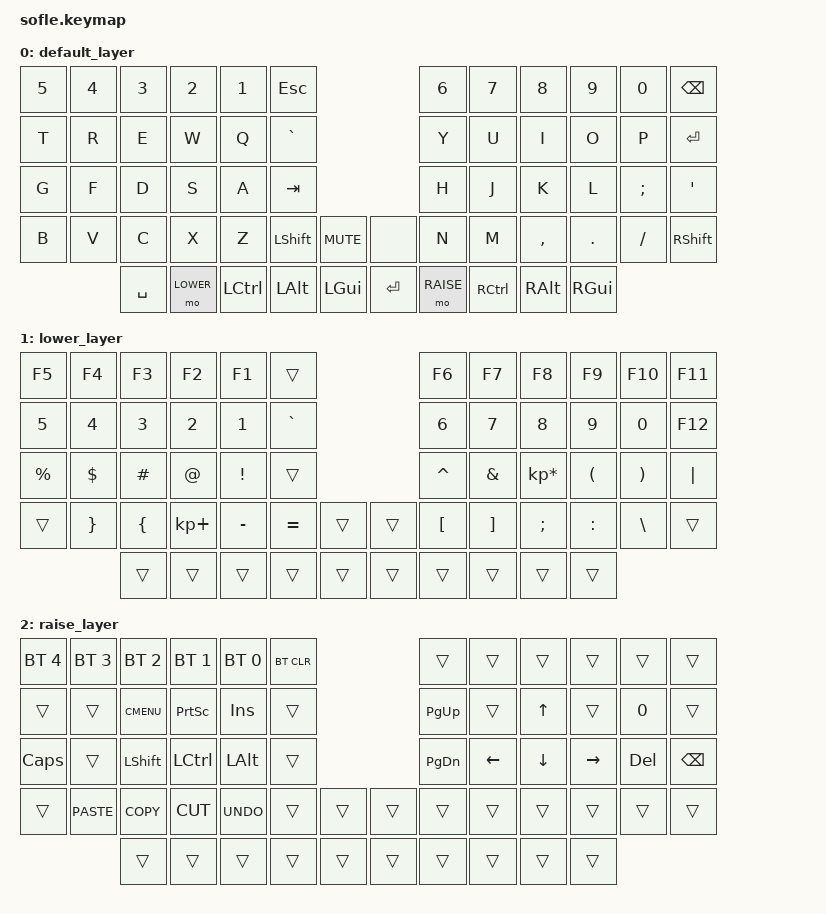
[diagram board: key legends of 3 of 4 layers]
/*
 * Copyright (c) 2020 The ZMK Contributors
 *
 * SPDX-License-Identifier: MIT
 */

#include <behaviors.dtsi>
#include <dt-bindings/zmk/keys.h>
#include <dt-bindings/zmk/bt.h>
#include <dt-bindings/zmk/rgb.h>
#include <dt-bindings/zmk/ext_power.h>

#define BASE 0
#define LOWER 1
#define RAISE 2
#define ADJUST 3

/ {

   // Activate ADJUST layer by pressing raise and lower
    conditional_layers {
        compatible = "zmk,conditional-layers";
        adjust_layer {
            if-layers = <LOWER RAISE>;
            then-layer = <ADJUST>;
        };
    };

    keymap {
        compatible = "zmk,keymap";

        default_layer {
// this is the keyhive variant which is a mirrored layout of the official sofle. be careful
// i.e. `QWERT is TREWQ`
// ------------------------------------------------------------------------------------------------------------
// |  ESC  |  1  |  2  |  3   |  4   |  5   |                   |  6   |  7    |  8    |  9   |   0   | BKSPC |
// |  `    |  Q  |  W  |  E   |  R   |  T   |                   |  Y   |  U    |  I    |  O   |   P   | ENTER |
// |  TAB  |  A  |  S  |  D   |  F   |  G   |                   |  H   |  J    |  K    |  L   |   ;   |   '   |
// | SHIFT |  Z  |  X  |  C   |  V   |  B   |  MUTE  |  |       |  N   |  M    |  ,    |  .   |   /   | SHIFT |
//               | GUI | ALT  | CTRL | LOWER|  SPACE |  | ENTER | RAISE| CTRL  | ALT   | GUI  |
            bindings = <
&kp N5 &kp N4 &kp N3   &kp N2   &kp N1    &kp ESC                      &kp N6 &kp N7    &kp N8    &kp N9   &kp N0   &kp BSPC
&kp  T &kp R  &kp E    &kp W    &kp Q     &kp GRAVE                     &kp Y  &kp U     &kp I     &kp O    &kp P    &kp RET
&kp G  &kp F  &kp D    &kp S    &kp A     &kp TAB                       &kp H  &kp J     &kp K     &kp L    &kp SEMI &kp SQT
&kp B  &kp V  &kp C &kp X       &kp Z     &kp LSHFT  &kp C_MUTE   &none     &kp N  &kp M     &kp COMMA &kp DOT  &kp FSLH &kp RSHFT
                 &kp SPACE &mo LOWER &kp LCTRL &kp LALT &kp LGUI   &kp RET &mo RAISE  &kp RCTRL &kp RALT  &kp RGUI
            >;

            sensor-bindings = <&inc_dec_kp C_VOL_UP C_VOL_DN &inc_dec_kp PG_UP PG_DN>;
        };

        lower_layer {
// TODO: Some binds are waiting for shifted keycode support.
// ------------------------------------------------------------------------------------------------------------
// |       |  F1 |  F2 |  F3  |  F4  |  F5  |                   |  F6  |  F7   |  F8   |  F9  |  F10  |  F11  |
// | `     |   1 |   2 |   3  |   4  |   5  |                   |   6  |   7   |   8   |   9  |    0  |  F12  |
// |       |  !  |  @  |  #   |  $   |  %   |                   |  ^   |  &    |  *    |  (   |   )   |   |   |
// |       |  =  |  -  |  +   |  {   |  }   |        |  |       |  [   |  ]    |  ;    |  :   |   \   |       |
//               |     |      |      |      |        |  |       |      |       |       |      |
            bindings = <
&kp F5   &kp F4     &kp F3    &kp F2      &kp F1    &trans                    &kp F6    &kp F7   &kp F8          &kp F9    &kp F10   &kp F11
&kp N5   &kp N4    &kp N3    &kp N2      &kp N1    &kp GRAVE                  &kp N6    &kp N7   &kp N8          &kp N9    &kp N0    &kp F12
&kp PRCNT &kp DLLR  &kp HASH    &kp AT    &kp EXCL  &trans                    &kp CARET &kp AMPS &kp KP_MULTIPLY &kp LPAR  &kp RPAR  &kp PIPE
&trans    &kp RBRC &kp LBRC &kp KP_PLUS &kp MINUS  &kp EQUAL  &trans   &trans &kp LBKT  &kp RBKT &kp SEMI        &kp COLON &kp BSLH  &trans
                    &trans    &trans      &trans    &trans    &trans   &trans &trans    &trans   &trans          &trans
            >;

            sensor-bindings = <&inc_dec_kp C_VOL_UP C_VOL_DN &inc_dec_kp PG_UP PG_DN>;
        };

        raise_layer {
// ------------------------------------------------------------------------------------------------------------
// |BTCLR| BT1  | BT2  |  BT3  |  BT4  |  BT5 |                |      |      |       |      |       |       |
// |     | INS  | PSCR | GUI   |       |      |                | PGUP |      |   ^   |      |       |       |
// |     | ALT  | CTRL | SHIFT |       | CAPS |                | PGDN |   <- |   v   |  ->  |  DEL  | BKSPC |
// |     | UNDO | CUT  | COPY  | PASTE |      |      |  |      |      |      |       |      |       |       |
//              |      |       |       |      |      |  |      |      |      |       |      |
            bindings = <
&bt BT_SEL 4 &bt BT_SEL 3 &bt BT_SEL 2 &bt BT_SEL 1 &bt BT_SEL 0 &bt BT_CLR             &trans    &trans    &trans   &trans    &trans  &trans
&trans     &trans       &kp K_CMENU    &kp PSCRN     &kp INS    &trans                   &kp PG_UP &trans    &kp UP   &trans    &kp N0  &trans
&kp CLCK   &trans      &kp LSHFT    &kp LCTRL    &kp LALT       &trans                 &kp PG_DN &kp LEFT  &kp DOWN &kp RIGHT &kp DEL &kp BSPC
&trans     &kp K_PASTE &kp K_COPY    &kp K_CUT   &kp K_UNDO  &trans  &trans   &trans  &trans    &trans    &trans   &trans    &trans  &trans
                        &trans       &trans       &trans       &trans  &trans   &trans  &trans    &trans    &trans   &trans
            >;

            sensor-bindings = <&inc_dec_kp C_VOL_UP C_VOL_DN &inc_dec_kp PG_UP PG_DN>;
        };

// ------------------------------------------------------------------------------------------------------------
// |BTCLR | BT1   | BT2   |  BT3  |  BT4  |  BT5  |                |      |      |       |      |       |       |
// |EXTPWR|RGB_HUD|RGB_HUI|RGB_SAD|RGB_SAI|RGB_EFF|                |      |      |       |      |       |       |
// |      |RGB_BRD|RGB_BRI|       |       |       |                |      |      |       |      |       |       |
// |      |       |       |       |       |       |RGB_TOG| |      |      |      |       |      |       |       |
//                |       |       |       |       |       | |      |      |      |       |      |

        Adjust_layer {
        bindings = <
&bt BT_SEL 4               &bt BT_SEL 3    &bt BT_SEL 2    &bt BT_SEL 1    &bt BT_SEL 0    &bt BT_CLR                                    &none &none &none &none &none &none
&rgb_ug RGB_EFF            &rgb_ug RGB_SAI &rgb_ug RGB_HUD &rgb_ug RGB_SAD &rgb_ug RGB_HUI &rgb_ug RGB_HUD &ext_power EXT_POWER_TOGGLE_CMD                                 &none &none &none &none &none &none
&none                      &none           &none           &rgb_ug RGB_BRI &rgb_ug RGB_BRD &none                                           &none &none &none &none &none &none
&rgb_ug RGB_TOG            &none           &none           &none           &none           &none     &none  &none      &none &none &none &none &none &none
                                                &none           &none           &none           &none               &none            &none      &none &none &none &none
        >;
        };

    };
};
